AUTOSAR XML (schema 4-0-3)
standard types defined: Boolean, uint8, UInt16, UInt32, UInt8
package /AUTOSAR_Platform/DataConstrs
  range DC_Boolean: raw 0..1
  range DC_UInt16: raw 0..65535
  range DC_UInt8: raw 0..255
package /PATAC/Facility/DataTypes/Implementation
  compu method COMPU_Boolean: 0=FALSE, 1=TRUE
  unit NoUnit: factor-si-to-unit=1, offset-si-to-unit=0
package /PATAC/MSM/ComponentTypes
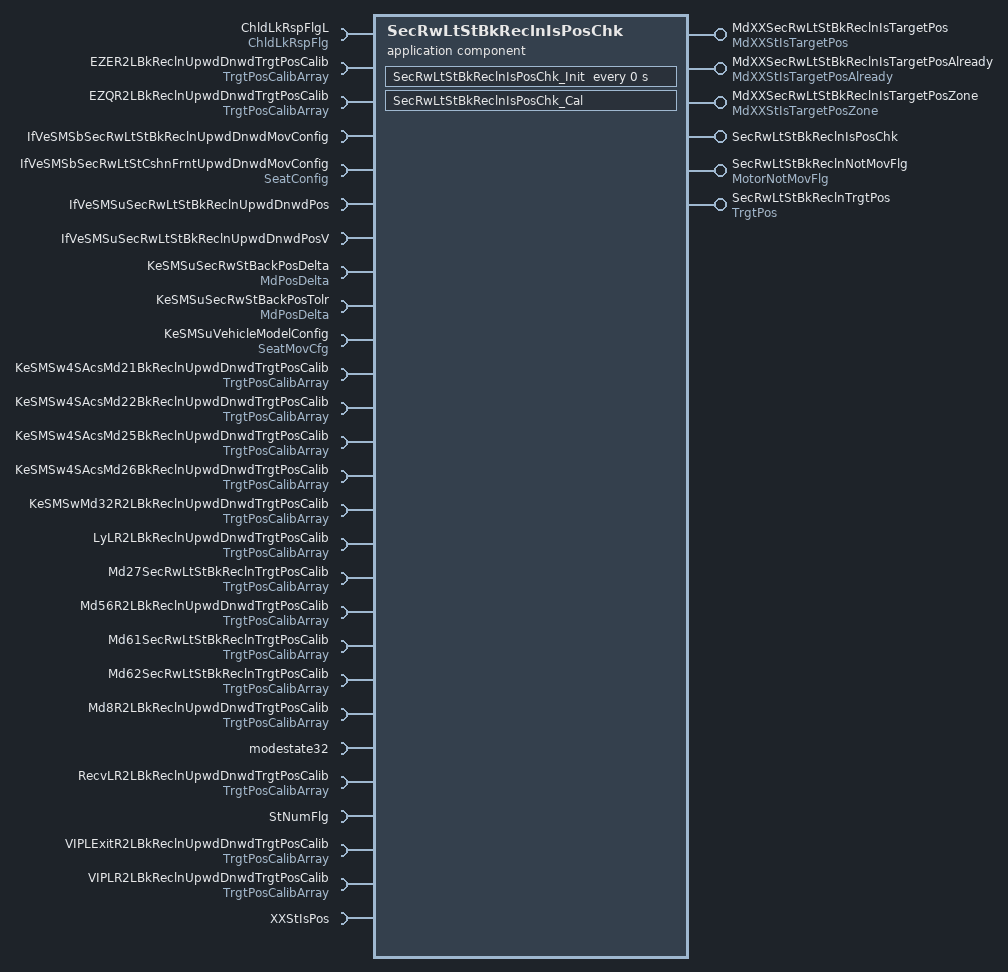
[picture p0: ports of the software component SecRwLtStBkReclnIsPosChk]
  application sw component type SecRwLtStBkReclnIsPosChk
    6 x provide port:
      MdXXSecRwLtStBkReclnIsTargetPos: nonqueued-sender-com-spec=data-element=MdXXStIsTargetPos/Val, provided-interface=MdXXStIsTargetPos
      MdXXSecRwLtStBkReclnIsTargetPosAlready: nonqueued-sender-com-spec=data-element=MdXXStIsTargetPosAlready/Val, provided-interface=MdXXStIsTargetPosAlready
      MdXXSecRwLtStBkReclnIsTargetPosZone: nonqueued-sender-com-spec=data-element=MdXXStIsTargetPosZone/Val, provided-interface=MdXXStIsTargetPosZone
      SecRwLtStBkReclnIsPosChk: server-com-spec{operation=Cal, queue-length=1}, provided-interface=SecRwLtStBkReclnIsPosChk
      SecRwLtStBkReclnNotMovFlg: nonqueued-sender-com-spec{data-element=MotorNotMovFlg/Val, init-value=0}, provided-interface=MotorNotMovFlg
      SecRwLtStBkReclnTrgtPos: nonqueued-sender-com-spec{data-element=TrgtPos/Val, init-value=4095}, provided-interface=TrgtPos
    27 x require port:
      ChldLkRspFlgL: nonqueued-receiver-com-spec{data-element=ChldLkRspFlg/Val, filter=data-filter-type=ALWAYS, init-value=0}, required-interface=ChldLkRspFlg
      EZER2LBkReclnUpwdDnwdTrgtPosCalib: nonqueued-receiver-com-spec{data-element=TrgtPosArray, filter=data-filter-type=ALWAYS, init-value=[4095, 4095, 4095]}, required-interface=TrgtPosCalibArray
      EZQR2LBkReclnUpwdDnwdTrgtPosCalib: nonqueued-receiver-com-spec{data-element=TrgtPosArray, filter=data-filter-type=ALWAYS, init-value=[4095, 4095, 4095]}, required-interface=TrgtPosCalibArray
      IfVeSMSbSecRwLtStBkReclnUpwdDnwdMovConfig: nonqueued-receiver-com-spec{data-element=IfVeSMSbSecRwLtStBkReclnUpwdDnwdMovConfig/Val, filter=data-filter-type=ALWAYS, init-value=0}, required-interface=IfVeSMSbSecRwLtStBkReclnUpwdDnwdMovConfig
      IfVeSMSbSecRwLtStCshnFrntUpwdDnwdMovConfig: nonqueued-receiver-com-spec{data-element=SeatConfig/Val, filter=data-filter-type=ALWAYS, init-value=0}, required-interface=SeatConfig
      IfVeSMSuSecRwLtStBkReclnUpwdDnwdPos: nonqueued-receiver-com-spec{data-element=IfVeSMSuSecRwLtStBkReclnUpwdDnwdPos/Val, filter=data-filter-type=ALWAYS, init-value=0}, required-interface=IfVeSMSuSecRwLtStBkReclnUpwdDnwdPos
      IfVeSMSuSecRwLtStBkReclnUpwdDnwdPosV: nonqueued-receiver-com-spec{data-element=IfVeSMSuSecRwLtStBkReclnUpwdDnwdPosV/Val, filter=data-filter-type=ALWAYS, init-value=0}, required-interface=IfVeSMSuSecRwLtStBkReclnUpwdDnwdPosV
      KeSMSuSecRwStBackPosDelta: parameter-require-com-spec{init-value=150, parameter=MdPosDelta/Val}, required-interface=MdPosDelta
      KeSMSuSecRwStBackPosTolr: parameter-require-com-spec{init-value=150, parameter=MdPosDelta/Val}, required-interface=MdPosDelta
      KeSMSuVehicleModelConfig: parameter-require-com-spec{init-value=2, parameter=SeatMovCfg/Val}, required-interface=SeatMovCfg
      KeSMSw4SAcsMd21BkReclnUpwdDnwdTrgtPosCalib: nonqueued-receiver-com-spec{data-element=TrgtPosArray, filter=data-filter-type=ALWAYS, init-value=[4095, 4095, 4095]}, required-interface=TrgtPosCalibArray
      KeSMSw4SAcsMd22BkReclnUpwdDnwdTrgtPosCalib: nonqueued-receiver-com-spec{data-element=TrgtPosArray, filter=data-filter-type=ALWAYS, init-value=[4095, 4095, 4095]}, required-interface=TrgtPosCalibArray
      KeSMSw4SAcsMd25BkReclnUpwdDnwdTrgtPosCalib: nonqueued-receiver-com-spec{data-element=TrgtPosArray, filter=data-filter-type=ALWAYS, init-value=[4095, 4095, 4095]}, required-interface=TrgtPosCalibArray
      KeSMSw4SAcsMd26BkReclnUpwdDnwdTrgtPosCalib: nonqueued-receiver-com-spec{data-element=TrgtPosArray, filter=data-filter-type=ALWAYS, init-value=[4095, 4095, 4095]}, required-interface=TrgtPosCalibArray
      KeSMSwMd32R2LBkReclnUpwdDnwdTrgtPosCalib: nonqueued-receiver-com-spec{data-element=TrgtPosArray, filter=data-filter-type=ALWAYS, init-value=[4095, 4095, 4095]}, required-interface=TrgtPosCalibArray
      LyLR2LBkReclnUpwdDnwdTrgtPosCalib: nonqueued-receiver-com-spec{data-element=TrgtPosArray, filter=data-filter-type=ALWAYS, init-value=[4095, 4095, 4095]}, required-interface=TrgtPosCalibArray
      Md27SecRwLtStBkReclnTrgtPosCalib: nonqueued-receiver-com-spec{data-element=TrgtPosArray, filter=data-filter-type=ALWAYS, init-value=[4095, 4095, 4095]}, required-interface=TrgtPosCalibArray
      Md56R2LBkReclnUpwdDnwdTrgtPosCalib: nonqueued-receiver-com-spec{data-element=TrgtPosArray, filter=data-filter-type=ALWAYS, init-value=[4095, 4095, 4095]}, required-interface=TrgtPosCalibArray
      Md61SecRwLtStBkReclnTrgtPosCalib: nonqueued-receiver-com-spec{data-element=TrgtPosArray, filter=data-filter-type=ALWAYS, init-value=[4095, 4095, 4095]}, required-interface=TrgtPosCalibArray
      Md62SecRwLtStBkReclnTrgtPosCalib: nonqueued-receiver-com-spec{data-element=TrgtPosArray, filter=data-filter-type=ALWAYS, init-value=[4095, 4095, 4095]}, required-interface=TrgtPosCalibArray
      Md8R2LBkReclnUpwdDnwdTrgtPosCalib: nonqueued-receiver-com-spec{data-element=TrgtPosArray, filter=data-filter-type=ALWAYS, init-value=[4095, 4095, 4095]}, required-interface=TrgtPosCalibArray
      modestate32: nonqueued-receiver-com-spec{data-element=modestate32/Val, filter=data-filter-type=ALWAYS, init-value=0}, required-interface=modestate32
      RecvLR2LBkReclnUpwdDnwdTrgtPosCalib: nonqueued-receiver-com-spec{data-element=TrgtPosArray, filter=data-filter-type=ALWAYS, init-value=[4095, 4095, 4095]}, required-interface=TrgtPosCalibArray
      StNumFlg: required-interface=StNumFlg
        required-com-specs:
          data-element=Is4s, filter=data-filter-type=ALWAYS, init-value=0
          data-element=Is6s, filter=data-filter-type=ALWAYS, init-value=0
          data-element=Is6s7s, filter=data-filter-type=ALWAYS, init-value=0
          data-element=Is7s, filter=data-filter-type=ALWAYS, init-value=0
      VIPLExitR2LBkReclnUpwdDnwdTrgtPosCalib: nonqueued-receiver-com-spec{data-element=TrgtPosArray, filter=data-filter-type=ALWAYS, init-value=[4095, 4095, 4095]}, required-interface=TrgtPosCalibArray
      VIPLR2LBkReclnUpwdDnwdTrgtPosCalib: nonqueued-receiver-com-spec{data-element=TrgtPosArray, filter=data-filter-type=ALWAYS, init-value=[4095, 4095, 4095]}, required-interface=TrgtPosCalibArray
      XXStIsPos: client-com-spec=Get, required-interface=XXStIsPos
    behavior SecRwLtStBkReclnIsPosChk_InternalBehavior
      operation invoked event OIT_SecRwLtStBkReclnIsPosChk_Cal_SecRwLtStBkReclnIsPosChk_Cal: start-on-event=SecRwLtStBkReclnIsPosChk_Cal, operation=SecRwLtStBkReclnIsPosChk.Cal
      timing event SecRwLtStBkReclnIsPosChk_InitEvent: start-on-event=SecRwLtStBkReclnIsPosChk_Init, period=0
      runnable SecRwLtStBkReclnIsPosChk_Cal
        data-receive-point-by-arguments:
          26 x access:
            REC_ChldLkRspFlgL_Val: accessed-variable=ChldLkRspFlgL.Val
            REC_EZER2LBkReclnUpwdDnwdTrgtPosCalib_TrgtPosArray: accessed-variable=EZER2LBkReclnUpwdDnwdTrgtPosCalib.TrgtPosArray
            REC_EZQR2LBkReclnUpwdDnwdTrgtPosCalib_TrgtPosArray: accessed-variable=EZQR2LBkReclnUpwdDnwdTrgtPosCalib.TrgtPosArray
            REC_IfVeSMSbSecRwLtStBkReclnUpwdDnwdMovConfig_Val: accessed-variable=IfVeSMSbSecRwLtStBkReclnUpwdDnwdMovConfig.Val
            REC_IfVeSMSbSecRwLtStCshnFrntUpwdDnwdMovConfig_Val: accessed-variable=IfVeSMSbSecRwLtStCshnFrntUpwdDnwdMovConfig.Val
            REC_IfVeSMSuSecRwLtStBkReclnUpwdDnwdPos_Val: accessed-variable=IfVeSMSuSecRwLtStBkReclnUpwdDnwdPos.Val
            REC_IfVeSMSuSecRwLtStBkReclnUpwdDnwdPosV_Val: accessed-variable=IfVeSMSuSecRwLtStBkReclnUpwdDnwdPosV.Val
            REC_KeSMSw4SAcsMd21BkReclnUpwdDnwdTrgtPosCalib_TrgtPosArray: accessed-variable=KeSMSw4SAcsMd21BkReclnUpwdDnwdTrgtPosCalib.TrgtPosArray
            REC_KeSMSw4SAcsMd22BkReclnUpwdDnwdTrgtPosCalib_TrgtPosArray: accessed-variable=KeSMSw4SAcsMd22BkReclnUpwdDnwdTrgtPosCalib.TrgtPosArray
            REC_KeSMSw4SAcsMd25BkReclnUpwdDnwdTrgtPosCalib_TrgtPosArray: accessed-variable=KeSMSw4SAcsMd25BkReclnUpwdDnwdTrgtPosCalib.TrgtPosArray
            REC_KeSMSw4SAcsMd26BkReclnUpwdDnwdTrgtPosCalib_TrgtPosArray: accessed-variable=KeSMSw4SAcsMd26BkReclnUpwdDnwdTrgtPosCalib.TrgtPosArray
            REC_KeSMSwMd32R2LBkReclnUpwdDnwdTrgtPosCalib_TrgtPosArray: accessed-variable=KeSMSwMd32R2LBkReclnUpwdDnwdTrgtPosCalib.TrgtPosArray
            REC_LyLR2LBkReclnUpwdDnwdTrgtPosCalib_TrgtPosArray: accessed-variable=LyLR2LBkReclnUpwdDnwdTrgtPosCalib.TrgtPosArray
            REC_Md27SecRwLtStBkReclnTrgtPosCalib_TrgtPosArray: accessed-variable=Md27SecRwLtStBkReclnTrgtPosCalib.TrgtPosArray
            REC_Md56R2LBkReclnUpwdDnwdTrgtPosCalib_TrgtPosArray: accessed-variable=Md56R2LBkReclnUpwdDnwdTrgtPosCalib.TrgtPosArray
            REC_Md61SecRwLtStBkReclnTrgtPosCalib_TrgtPosArray: accessed-variable=Md61SecRwLtStBkReclnTrgtPosCalib.TrgtPosArray
            REC_Md62SecRwLtStBkReclnTrgtPosCalib_TrgtPosArray: accessed-variable=Md62SecRwLtStBkReclnTrgtPosCalib.TrgtPosArray
            REC_Md8R2LBkReclnUpwdDnwdTrgtPosCalib_TrgtPosArray: accessed-variable=Md8R2LBkReclnUpwdDnwdTrgtPosCalib.TrgtPosArray
            REC_modestate32_Val: accessed-variable=modestate32.Val
            REC_RecvLR2LBkReclnUpwdDnwdTrgtPosCalib_TrgtPosArray: accessed-variable=RecvLR2LBkReclnUpwdDnwdTrgtPosCalib.TrgtPosArray
            REC_StNumFlg_Is4s: accessed-variable=StNumFlg.Is4s
            REC_StNumFlg_Is6s: accessed-variable=StNumFlg.Is6s
            REC_StNumFlg_Is6s7s: accessed-variable=StNumFlg.Is6s7s
            REC_StNumFlg_Is7s: accessed-variable=StNumFlg.Is7s
            REC_VIPLExitR2LBkReclnUpwdDnwdTrgtPosCalib_TrgtPosArray: accessed-variable=VIPLExitR2LBkReclnUpwdDnwdTrgtPosCalib.TrgtPosArray
            REC_VIPLR2LBkReclnUpwdDnwdTrgtPosCalib_TrgtPosArray: accessed-variable=VIPLR2LBkReclnUpwdDnwdTrgtPosCalib.TrgtPosArray
        data-send-points:
          5 x access:
            SEND_MdXXSecRwLtStBkReclnIsTargetPos_Val: accessed-variable=MdXXSecRwLtStBkReclnIsTargetPos.Val
            SEND_MdXXSecRwLtStBkReclnIsTargetPosAlready_Val: accessed-variable=MdXXSecRwLtStBkReclnIsTargetPosAlready.Val
            SEND_MdXXSecRwLtStBkReclnIsTargetPosZone_Val: accessed-variable=MdXXSecRwLtStBkReclnIsTargetPosZone.Val
            SEND_SecRwLtStBkReclnNotMovFlg_Val: accessed-variable=SecRwLtStBkReclnNotMovFlg.Val
            SEND_SecRwLtStBkReclnTrgtPos_Val: accessed-variable=SecRwLtStBkReclnTrgtPos.Val
        parameter access PA_KeSMSuSecRwStBackPosDelta_Val: accessed-parameter=KeSMSuSecRwStBackPosDelta.Val
        parameter access PA_KeSMSuSecRwStBackPosTolr_Val: accessed-parameter=KeSMSuSecRwStBackPosTolr.Val
        parameter access PA_KeSMSuVehicleModelConfig_Val: accessed-parameter=KeSMSuVehicleModelConfig.Val
        sync call SC_XXStIsPos_Get: operation=XXStIsPos.Get, timeout=0
      runnable SecRwLtStBkReclnIsPosChk_Init
        parameter access PA_KeSMSuSecRwStBackPosDelta_Val: accessed-parameter=KeSMSuSecRwStBackPosDelta.Val
        parameter access PA_KeSMSuSecRwStBackPosTolr_Val: accessed-parameter=KeSMSuSecRwStBackPosTolr.Val
        parameter access PA_KeSMSuVehicleModelConfig_Val: accessed-parameter=KeSMSuVehicleModelConfig.Val
  swc implementation SecRwLtStBkReclnIsPosChk_Implementation: behavior=SecRwLtStBkReclnIsPosChk_InternalBehavior
    code-descriptors:
      code Default: artifact-descriptors=autosar-engineering-object={short-label=Default, category=SWSRC}
package /PATAC/MSM/DataTypes
  parameter interface SeatMovCfg
    parameter data prototype Val: sw-calibration-access=READ-WRITE, type=UInt8
package /PATAC/MSM/ModeAdjust/CalPortInterface
  parameter interface MdPosDelta
    parameter data prototype Val: sw-calibration-access=READ-WRITE, type=UInt16
package /PATAC/MSM/ModeAdjust/DataType
  impl type TrgtPosCalibArray: category=ARRAY, sw-calibration-access=READ-ONLY, type-emitter=RTE  # 0:pos 1:max 2:min
    element Element: array-size=3, array-size-semantics=FIXED-SIZE, implementation-data-type=UInt16, invalid-value=0
package /PATAC/MSM/ModeAdjust/Interfaces
  sender receiver interface IfVeSMSuSecRwLtStBkReclnUpwdDnwdPosV: invalidation-policy{data-element=IfVeSMSuSecRwLtStBkReclnUpwdDnwdPosV/Val, handle-invalid=DONT-INVALIDATE}
    data Val: type=Implementation/Boolean
package /PATAC/MSM/ModeAdjust/PortInterface
  client server interface SecRwLtStBkReclnIsPosChk
    operation Cal
  client server interface XXStIsPos
    operation Get
      8 x arg, all with server-argument-impl-policy=USE-ARGUMENT-TYPE:
        PosV: type=DataTypes/Boolean, direction=IN
        Pos: type=UInt16, direction=IN
        CalibArray: type=TrgtPosCalibArray, direction=IN
        Delta: type=UInt16, direction=IN
        Tolr: type=UInt16, direction=IN
        IsPos: type=DataTypes/Boolean, direction=OUT
        IsPosZone: type=DataTypes/Boolean, direction=OUT
        IsPosAlready: type=DataTypes/Boolean, direction=OUT
  8 x sender receiver interface:
    ChldLkRspFlg: invalidation-policy{data-element=ChldLkRspFlg/Val, handle-invalid=DONT-INVALIDATE}
      data Val: type=Implementation/Boolean
    MdXXStIsTargetPos: invalidation-policy{data-element=MdXXStIsTargetPos/Val, handle-invalid=DONT-INVALIDATE}
      data Val: type=UInt32
    MdXXStIsTargetPosAlready: invalidation-policy{data-element=MdXXStIsTargetPosAlready/Val, handle-invalid=DONT-INVALIDATE}
      data Val: type=UInt32
    MdXXStIsTargetPosZone: invalidation-policy{data-element=MdXXStIsTargetPosZone/Val, handle-invalid=DONT-INVALIDATE}
      data Val: type=UInt32
    modestate32: invalidation-policy{data-element=modestate32/Val, handle-invalid=DONT-INVALIDATE}
      data Val: type=UInt32
    MotorNotMovFlg: invalidation-policy{data-element=MotorNotMovFlg/Val, handle-invalid=DONT-INVALIDATE}
      data Val: type=Implementation/Boolean
    StNumFlg
      4 x data, all with type=Implementation/Boolean:
        Is4s
        Is6s
        Is6s7s
        Is7s
      invalidation-policys:
        data-element=Is4s, handle-invalid=DONT-INVALIDATE
        data-element=Is6s, handle-invalid=DONT-INVALIDATE
        data-element=Is6s7s, handle-invalid=DONT-INVALIDATE
        data-element=Is7s, handle-invalid=DONT-INVALIDATE
    TrgtPosCalibArray: invalidation-policy{data-element=TrgtPosArray, handle-invalid=DONT-INVALIDATE}
      data TrgtPosArray: type=TrgtPosCalibArray  # 0:Pos 1:Max 2:Min
package /PATAC/MSM/PortInterfaces
  4 x sender receiver interface:
    IfVeSMSbSecRwLtStBkReclnUpwdDnwdMovConfig: invalidation-policy{data-element=IfVeSMSbSecRwLtStBkReclnUpwdDnwdMovConfig/Val, handle-invalid=DONT-INVALIDATE}
      data Val: type=Implementation/Boolean
    IfVeSMSuSecRwLtStBkReclnUpwdDnwdPos: invalidation-policy{data-element=IfVeSMSuSecRwLtStBkReclnUpwdDnwdPos/Val, handle-invalid=DONT-INVALIDATE}
      data Val: type=UInt16
    SeatConfig: invalidation-policy{data-element=SeatConfig/Val, handle-invalid=DONT-INVALIDATE}
      data Val: type=Implementation/Boolean
    TrgtPos: invalidation-policy{data-element=TrgtPos/Val, handle-invalid=DONT-INVALIDATE}
      data Val: type=UInt16
